VERSION "DBC Pylontech"

NS_ :

BU_: US2000B

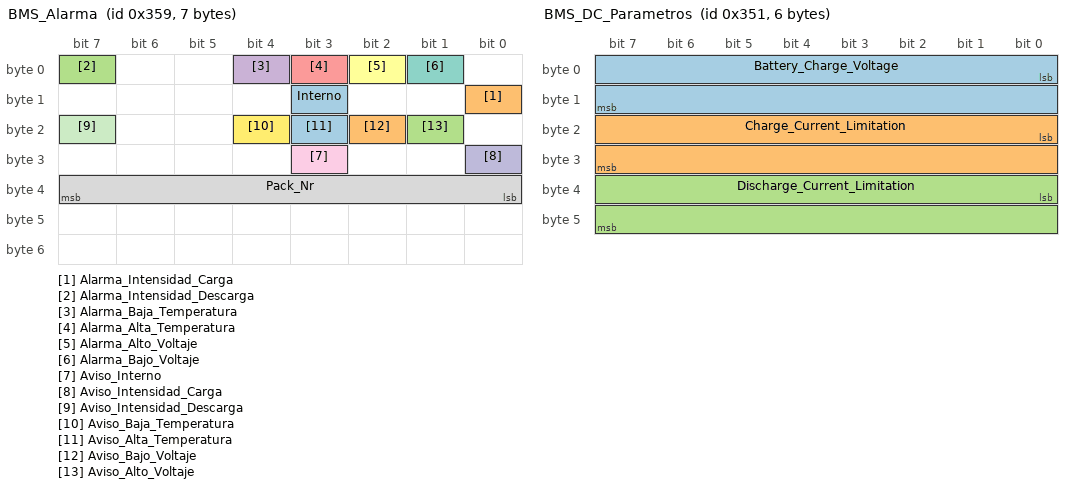
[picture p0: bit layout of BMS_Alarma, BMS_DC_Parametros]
BO_ 857 BMS_Alarma: 7 US2000B
  SG_ Interno                      :  11|1@0+  (1,0)         [0|1]          ""   US2000B
  SG_ Alarma_Intensidad_Carga      :   8|1@0+  (1,0)         [0|1]          ""   US2000B
  SG_ Alarma_Intensidad_Descarga   :   7|1@0+  (1,0)         [0|1]          ""   US2000B
  SG_ Alarma_Baja_Temperatura      :   4|1@0+  (1,0)         [0|1]          ""   US2000B
  SG_ Alarma_Alta_Temperatura      :   3|1@0+  (1,0)         [0|1]          ""   US2000B
  SG_ Alarma_Alto_Voltaje          :   2|1@0+  (1,0)         [0|1]          ""   US2000B
  SG_ Alarma_Bajo_Voltaje          :   1|1@0+  (1,0)         [0|1]          ""   US2000B

  SG_ Pack_Nr                      :  32|8@1+  (1,0)         [0|255]        ""   US2000B
  SG_ Aviso_Interno                :  27|1@0+  (1,0)         [0|1]          ""   US2000B
  SG_ Aviso_Intensidad_Carga       :  24|1@0+  (1,0)         [0|1]          ""   US2000B

  SG_ Aviso_Intensidad_Descarga    :  23|1@0+  (1,0)         [0|1]          ""   US2000B
  SG_ Aviso_Baja_Temperatura         :  20|1@0+  (1,0)         [0|1]          ""   US2000B
  SG_ Aviso_Alta_Temperatura        :  19|1@0+  (1,0)         [0|1]          ""   US2000B
  SG_ Aviso_Bajo_Voltaje             :  18|1@0+  (1,0)         [0|1]          ""   US2000B
  SG_ Aviso_Alto_Voltaje            :  17|1@0+  (1,0)         [0|1]          ""   US2000B

BO_ 849 BMS_DC_Parametros: 6 US2000B
  SG_ Battery_Charge_Voltage           :   0|16@1+ (0.1,0)       [0|65.5]       "V"   US2000B
  SG_ Charge_Current_Limitation        :  16|16@1- (0.1,0)       [0|100]        "A"   US2000B
  SG_ Discharge_Current_Limitation     :  32|16@1- (0.1,0)       [0|100]        "A"   US2000B

BO_ 853 BMS_State: 4 US2000B
  SG_ SOC              :   0|16@1+ (1,0)         [0|100]        "%"   US2000B
  SG_ SOH              :  16|16@1+ (1,0)         [0|100]        "%"   US2000B

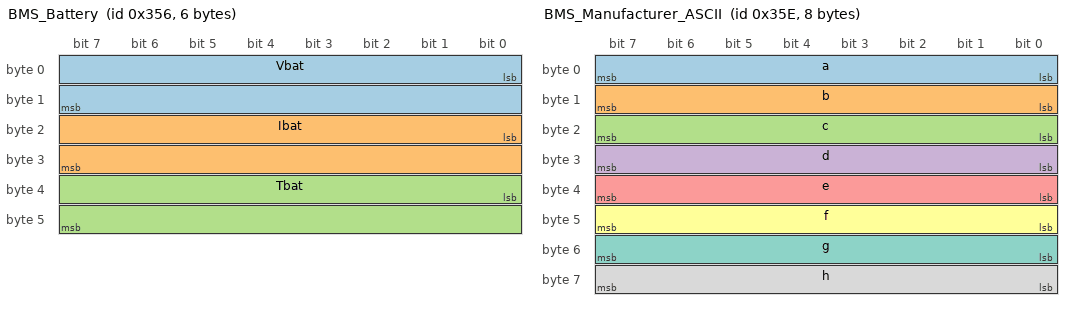
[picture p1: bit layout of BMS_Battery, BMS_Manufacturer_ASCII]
BO_ 854 BMS_Battery: 6 US2000B
  SG_ Vbat     :   0|16@1- (0.01,0)      [0|65.5]       "V"   US2000B
  SG_ Ibat     :  16|16@1- (0.1,0)       [-100|100]     "A"   US2000B
  SG_ Tbat     :  32|16@1- (0.1,0)       [-20|100]      "degC"   US2000B

BO_ 862 BMS_Manufacturer_ASCII: 8 US2000B
  SG_ a              :   0|8@1+ (1,0)         [0|255]        ""   US2000B
  SG_ b              :   8|8@1+ (1,0)         [0|255]        ""   US2000B
  SG_ c              :  16|8@1+ (1,0)         [0|255]        ""   US2000B
  SG_ d              :  24|8@1+ (1,0)         [0|255]        ""   US2000B
  SG_ e              :  32|8@1+ (1,0)         [0|255]        ""   US2000B
  SG_ f              :  40|8@1+ (1,0)         [0|255]        ""   US2000B
  SG_ g              :  48|8@1+ (1,0)         [0|255]        ""   US2000B
  SG_ h              :  56|8@1+ (1,0)         [0|255]        ""   US2000B

VAL_ 862 a 32 " " 65 "A" 66 "B" 67 "C" 68 "D" 69 "E" 70 "F" 71 "G" 72 "H" 73 "I" 74 "J" 75 "K" 76 "L" 77 "M" 78 "N" 79 "O" 80 "P" 81 "Q" 82 "R" 83 "S" 84 "T" 85 "U" 86 "V" 87 "W" 88 "X" 89 "Y" 90 "Z";
VAL_ 862 b 32 " " 65 "A" 66 "B" 67 "C" 68 "D" 69 "E" 70 "F" 71 "G" 72 "H" 73 "I" 74 "J" 75 "K" 76 "L" 77 "M" 78 "N" 79 "O" 80 "P" 81 "Q" 82 "R" 83 "S" 84 "T" 85 "U" 86 "V" 87 "W" 88 "X" 89 "Y" 90 "Z";
VAL_ 862 c 32 " " 65 "A" 66 "B" 67 "C" 68 "D" 69 "E" 70 "F" 71 "G" 72 "H" 73 "I" 74 "J" 75 "K" 76 "L" 77 "M" 78 "N" 79 "O" 80 "P" 81 "Q" 82 "R" 83 "S" 84 "T" 85 "U" 86 "V" 87 "W" 88 "X" 89 "Y" 90 "Z";
VAL_ 862 d 32 " " 65 "A" 66 "B" 67 "C" 68 "D" 69 "E" 70 "F" 71 "G" 72 "H" 73 "I" 74 "J" 75 "K" 76 "L" 77 "M" 78 "N" 79 "O" 80 "P" 81 "Q" 82 "R" 83 "S" 84 "T" 85 "U" 86 "V" 87 "W" 88 "X" 89 "Y" 90 "Z";
VAL_ 862 e 32 " " 65 "A" 66 "B" 67 "C" 68 "D" 69 "E" 70 "F" 71 "G" 72 "H" 73 "I" 74 "J" 75 "K" 76 "L" 77 "M" 78 "N" 79 "O" 80 "P" 81 "Q" 82 "R" 83 "S" 84 "T" 85 "U" 86 "V" 87 "W" 88 "X" 89 "Y" 90 "Z";
VAL_ 862 f 32 " " 65 "A" 66 "B" 67 "C" 68 "D" 69 "E" 70 "F" 71 "G" 72 "H" 73 "I" 74 "J" 75 "K" 76 "L" 77 "M" 78 "N" 79 "O" 80 "P" 81 "Q" 82 "R" 83 "S" 84 "T" 85 "U" 86 "V" 87 "W" 88 "X" 89 "Y" 90 "Z";
VAL_ 862 g 32 " " 65 "A" 66 "B" 67 "C" 68 "D" 69 "E" 70 "F" 71 "G" 72 "H" 73 "I" 74 "J" 75 "K" 76 "L" 77 "M" 78 "N" 79 "O" 80 "P" 81 "Q" 82 "R" 83 "S" 84 "T" 85 "U" 86 "V" 87 "W" 88 "X" 89 "Y" 90 "Z";
VAL_ 862 h 32 " " 65 "A" 66 "B" 67 "C" 68 "D" 69 "E" 70 "F" 71 "G" 72 "H" 73 "I" 74 "J" 75 "K" 76 "L" 77 "M" 78 "N" 79 "O" 80 "P" 81 "Q" 82 "R" 83 "S" 84 "T" 85 "U" 86 "V" 87 "W" 88 "X" 89 "Y" 90 "Z";

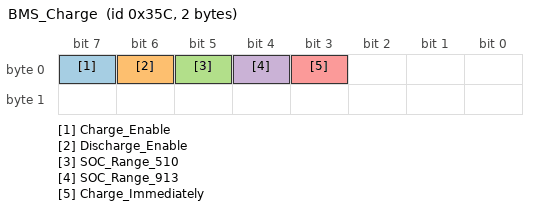
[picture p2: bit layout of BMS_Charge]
BO_ 860 BMS_Charge: 2 US2000B
  SG_ Charge_Enable      :  7|1@1+ (1,0)         [0|1]        ""   US2000B
  SG_ Discharge_Enable   :  6|1@1+ (1,0)         [0|1]        ""   US2000B
  SG_ SOC_Range_510 :  5|1@1+ (1,0)         [0|1]        ""   US2000B
  SG_ SOC_Range_913 :  4|1@1+ (1,0)         [0|1]        ""   US2000B
  SG_ Charge_Immediately :  3|1@1+ (1,0)         [0|1]        ""   US2000B

CM_ BU_ US2000B "Pylontech US2000B BMS";
